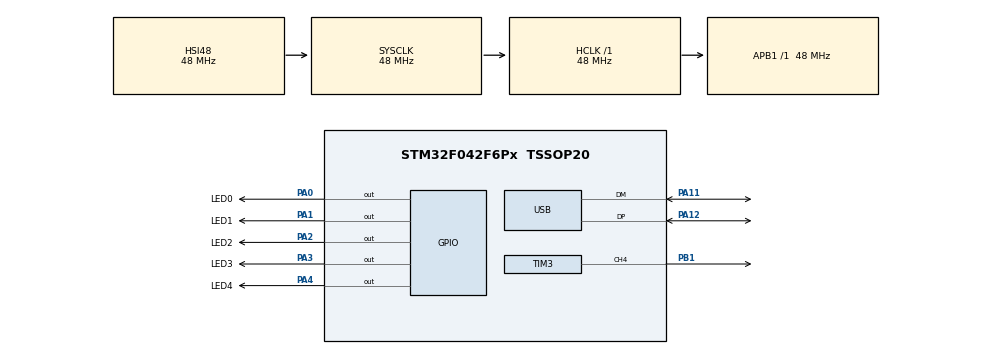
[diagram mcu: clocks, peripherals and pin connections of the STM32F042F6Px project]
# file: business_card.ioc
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Mcu.Family=STM32F0
Mcu.Name=STM32F042F6Px
Mcu.Package=TSSOP20
NVIC.USB_IRQn=true\:0\:0\:false\:false\:true\:false\:true\:true
PA0.GPIO_Label=LED0
PA0.Signal=GPIO_Output
PA1.GPIO_Label=LED1
PA1.Signal=GPIO_Output
PA11.Mode=Device
PA11.Signal=USB_DM
PA12.Mode=Device
PA12.Signal=USB_DP
PA13.Mode=Serial_Wire
PA13.Signal=SYS_SWDIO
PA14.Mode=Serial_Wire
PA14.Signal=SYS_SWCLK
PA2.GPIO_Label=LED2
PA2.Signal=GPIO_Output
PA3.GPIO_Label=LED3
PA3.Signal=GPIO_Output
PA4.GPIO_Label=LED4
PA4.Signal=GPIO_Output
PB1.Signal=S_TIM3_CH4
ProjectManager.HeapSize=0x200
ProjectManager.StackSize=0x400
ProjectManager.TargetToolchain=Makefile
RCC.AHBFreq_Value=48000000
RCC.APB1Freq_Value=48000000
RCC.APB1TimFreq_Value=48000000
RCC.HCLKFreq_Value=48000000
RCC.SYSCLKFreq_VALUE=48000000
RCC.SYSCLKSource=RCC_SYSCLKSOURCE_HSI48
SH.S_TIM3_CH4.0=TIM3_CH4,PWM Generation4 CH4
TIM3.Channel-PWM\ Generation4\ CH4=TIM_CHANNEL_4
TIM3.OC4Preload_PWM=DISABLE
TIM3.Period=6000
TIM3.Pulse-PWM\ Generation4\ CH4=3000
USB_DEVICE.APP_RX_DATA_SIZE=64
USB_DEVICE.APP_TX_DATA_SIZE=64
USB_DEVICE.CLASS_NAME_FS=CDC
USB_DEVICE.MANUFACTURER_STRING=RariTech
USB_DEVICE.PRODUCT_STRING_CDC_FS=Business Card
USB_DEVICE.USBD_MAX_STR_DESC_SIZ=32
USB_DEVICE.VirtualMode=Cdc
USB_DEVICE.VirtualModeFS=Cdc_FS
VP_SYS_VS_PINREMAP.Mode=PINREMAP
VP_USB_DEVICE_VS_USB_DEVICE_CDC_FS.Mode=CDC_FS
board=custom

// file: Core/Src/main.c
/* USER CODE BEGIN Header */
/**
  ******************************************************************************
  * @file           : main.c
  * @brief          : Main program body
  ******************************************************************************
  * @attention
  *
  * Copyright (c) 2023 STMicroelectronics.
  * All rights reserved.
  *
  * This software is licensed under terms that can be found in the LICENSE file
  * in the root directory of this software component.
  * If no LICENSE file comes with this software, it is provided AS-IS.
  *
  ******************************************************************************
  */
/* USER CODE END Header */
#include "main.h"
#include "usb_device.h"

/* USER CODE BEGIN Includes */
#include "shape_moves.h"
/* USER CODE END Includes */

TIM_HandleTypeDef htim3;

void SystemClock_Config(void);
static void MX_GPIO_Init(void);
static void MX_TIM3_Init(void);

int main(void)
{

  /* MCU Configuration--------------------------------------------------------*/

  /* Reset of all peripherals, Initializes the Flash interface and the Systick. */
  HAL_Init();

  /* Configure the system clock */
  SystemClock_Config();

  /* Initialize all configured peripherals */
  MX_GPIO_Init();
  MX_TIM3_Init();
  MX_USB_DEVICE_Init();
  /* USER CODE BEGIN 2 */
  char field[(MAX_ROWS+STAGE_SIZE)*MAX_COLUMNS];
  /* USER CODE END 2 */

  /* Infinite loop */
  while (1)
  {
    checkFinished(field);
    HAL_Delay(1000);
  }
}

void SystemClock_Config(void)
{
  RCC_OscInitTypeDef RCC_OscInitStruct = {0};
  RCC_ClkInitTypeDef RCC_ClkInitStruct = {0};
  RCC_PeriphCLKInitTypeDef PeriphClkInit = {0};

  /** Initializes the RCC Oscillators according to the specified parameters
  * in the RCC_OscInitTypeDef structure.
  */
  RCC_OscInitStruct.OscillatorType = RCC_OSCILLATORTYPE_HSI48;
  RCC_OscInitStruct.HSI48State = RCC_HSI48_ON;
  RCC_OscInitStruct.PLL.PLLState = RCC_PLL_NONE;
  if (HAL_RCC_OscConfig(&RCC_OscInitStruct) != HAL_OK)
  {
    Error_Handler();
  }

  /** Initializes the CPU, AHB and APB buses clocks
  */
  RCC_ClkInitStruct.ClockType = RCC_CLOCKTYPE_HCLK|RCC_CLOCKTYPE_SYSCLK
                              |RCC_CLOCKTYPE_PCLK1;
  RCC_ClkInitStruct.SYSCLKSource = RCC_SYSCLKSOURCE_HSI48;
  RCC_ClkInitStruct.AHBCLKDivider = RCC_SYSCLK_DIV1;
  RCC_ClkInitStruct.APB1CLKDivider = RCC_HCLK_DIV1;

  if (HAL_RCC_ClockConfig(&RCC_ClkInitStruct, FLASH_LATENCY_1) != HAL_OK)
  {
    Error_Handler();
  }
  PeriphClkInit.PeriphClockSelection = RCC_PERIPHCLK_USB;
  PeriphClkInit.UsbClockSelection = RCC_USBCLKSOURCE_HSI48;

  if (HAL_RCCEx_PeriphCLKConfig(&PeriphClkInit) != HAL_OK)
  {
    Error_Handler();
  }
}

static void MX_TIM3_Init(void)
{

  TIM_MasterConfigTypeDef sMasterConfig = {0};
  TIM_OC_InitTypeDef sConfigOC = {0};

  htim3.Instance = TIM3;
  htim3.Init.Prescaler = 0;
  htim3.Init.CounterMode = TIM_COUNTERMODE_UP;
  htim3.Init.Period = 6000;
  htim3.Init.ClockDivision = TIM_CLOCKDIVISION_DIV1;
  htim3.Init.AutoReloadPreload = TIM_AUTORELOAD_PRELOAD_DISABLE;
  if (HAL_TIM_PWM_Init(&htim3) != HAL_OK)
  {
    Error_Handler();
  }
  sMasterConfig.MasterOutputTrigger = TIM_TRGO_RESET;
  sMasterConfig.MasterSlaveMode = TIM_MASTERSLAVEMODE_DISABLE;
  if (HAL_TIMEx_MasterConfigSynchronization(&htim3, &sMasterConfig) != HAL_OK)
  {
    Error_Handler();
  }
  sConfigOC.OCMode = TIM_OCMODE_PWM1;
  sConfigOC.Pulse = 3000;
  sConfigOC.OCPolarity = TIM_OCPOLARITY_HIGH;
  sConfigOC.OCFastMode = TIM_OCFAST_DISABLE;
  if (HAL_TIM_PWM_ConfigChannel(&htim3, &sConfigOC, TIM_CHANNEL_4) != HAL_OK)
  {
    Error_Handler();
  }
  __HAL_TIM_DISABLE_OCxPRELOAD(&htim3, TIM_CHANNEL_4);
  HAL_TIM_MspPostInit(&htim3);

}

static void MX_GPIO_Init(void)
{
  GPIO_InitTypeDef GPIO_InitStruct = {0};

  /* GPIO Ports Clock Enable */
  __HAL_RCC_GPIOA_CLK_ENABLE();
  __HAL_RCC_GPIOB_CLK_ENABLE();

  /*Configure GPIO pin Output Level */
  HAL_GPIO_WritePin(GPIOA, LED0_Pin|LED1_Pin|LED2_Pin|LED3_Pin
                          |LED4_Pin, GPIO_PIN_RESET);

  /*Configure GPIO pins : LED0_Pin LED1_Pin LED2_Pin LED3_Pin
                           LED4_Pin */
  GPIO_InitStruct.Pin = LED0_Pin|LED1_Pin|LED2_Pin|LED3_Pin
                          |LED4_Pin;
  GPIO_InitStruct.Mode = GPIO_MODE_OUTPUT_PP;
  GPIO_InitStruct.Pull = GPIO_NOPULL;
  GPIO_InitStruct.Speed = GPIO_SPEED_FREQ_LOW;
  HAL_GPIO_Init(GPIOA, &GPIO_InitStruct);

}

void Error_Handler(void)
{
  __disable_irq();
  while (1)
  {
  }
}
